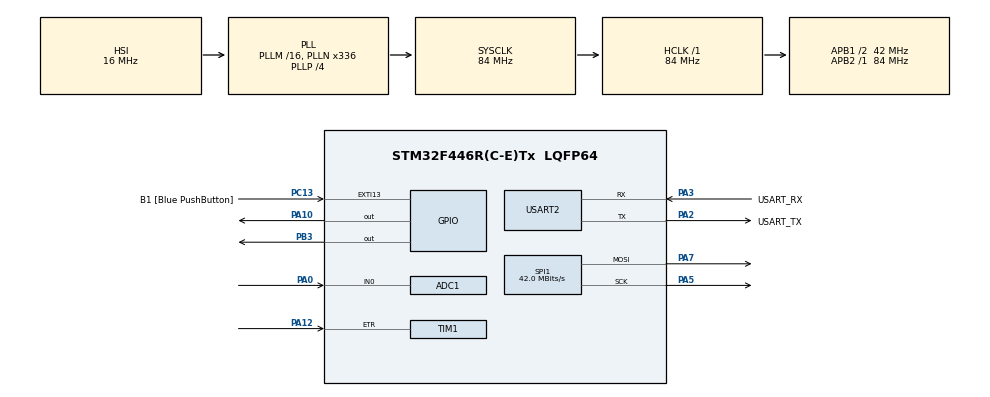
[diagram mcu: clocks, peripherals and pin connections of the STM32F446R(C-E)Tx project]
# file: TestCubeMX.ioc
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ADC1.Channel-6\#ChannelRegularConversion=ADC_CHANNEL_0
ADC1.NbrOfConversionFlag=1
ADC1.Rank-6\#ChannelRegularConversion=1
ADC1.SamplingTime-6\#ChannelRegularConversion=ADC_SAMPLETIME_3CYCLES
ADC1.master=1
Dma.Request0=SPI1_TX
Dma.SPI1_TX.0.Direction=DMA_MEMORY_TO_PERIPH
Dma.SPI1_TX.0.FIFOMode=DMA_FIFOMODE_DISABLE
Dma.SPI1_TX.0.Instance=DMA2_Stream3
Dma.SPI1_TX.0.MemDataAlignment=DMA_MDATAALIGN_BYTE
Dma.SPI1_TX.0.MemInc=DMA_MINC_ENABLE
Dma.SPI1_TX.0.Mode=DMA_NORMAL
Dma.SPI1_TX.0.PeriphDataAlignment=DMA_PDATAALIGN_BYTE
Dma.SPI1_TX.0.PeriphInc=DMA_PINC_DISABLE
Dma.SPI1_TX.0.Priority=DMA_PRIORITY_HIGH
Mcu.Family=STM32F4
Mcu.Name=STM32F446R(C-E)Tx
Mcu.Package=LQFP64
NVIC.DMA2_Stream3_IRQn=true\:0\:0\:false\:false\:true\:false\:true
NVIC.PriorityGroup=NVIC_PRIORITYGROUP_0
PA0-WKUP.Signal=ADCx_IN0
PA10.Signal=GPIO_Output
PA12.Signal=S_TIM1_ETR
PA13.GPIO_Label=TMS
PA13.Mode=Serial_Wire
PA13.Signal=SYS_JTMS-SWDIO
PA14.GPIO_Label=TCK
PA14.Mode=Serial_Wire
PA14.Signal=SYS_JTCK-SWCLK
PA2.GPIO_Label=USART_TX
PA2.Mode=Asynchronous
PA2.Signal=USART2_TX
PA3.GPIO_Label=USART_RX
PA3.Mode=Asynchronous
PA3.Signal=USART2_RX
PA5.Mode=TX_Only_Simplex_Unidirect_Master
PA5.Signal=SPI1_SCK
PA7.Mode=TX_Only_Simplex_Unidirect_Master
PA7.Signal=SPI1_MOSI
PB3.Signal=GPIO_Output
PC13.GPIO_Label=B1 [Blue PushButton]
PC13.GPIO_ModeDefaultEXTI=GPIO_MODE_IT_FALLING
PC13.Signal=GPXTI13
PC14-OSC32_IN.Mode=LSE-External-Oscillator
PC14-OSC32_IN.Signal=RCC_OSC32_IN
PC15-OSC32_OUT.Mode=LSE-External-Oscillator
PC15-OSC32_OUT.Signal=RCC_OSC32_OUT
PH0-OSC_IN.Mode=HSE-External-Oscillator
PH0-OSC_IN.Signal=RCC_OSC_IN
PH1-OSC_OUT.Mode=HSE-External-Oscillator
PH1-OSC_OUT.Signal=RCC_OSC_OUT
ProjectManager.HeapSize=0x200
ProjectManager.StackSize=0x400
ProjectManager.TargetToolchain=STM32CubeIDE
RCC.48MHZClocksFreq_Value=84000000
RCC.AHBFreq_Value=84000000
RCC.APB1CLKDivider=RCC_HCLK_DIV2
RCC.APB1Freq_Value=42000000
RCC.APB1TimFreq_Value=84000000
RCC.APB2Freq_Value=84000000
RCC.APB2TimFreq_Value=84000000
RCC.CortexFreq_Value=84000000
RCC.FLatency-AdvancedSettings=FLASH_LATENCY_2
RCC.HCLKFreq_Value=84000000
RCC.HSE_VALUE=8000000
RCC.HSI_VALUE=16000000
RCC.PLLN=336
RCC.PLLP=RCC_PLLP_DIV4
RCC.SYSCLKFreq_VALUE=84000000
RCC.SYSCLKSource=RCC_SYSCLKSOURCE_PLLCLK
RCC.USBFreq_Value=168000000
RCC.VCOOutputFreq_Value=336000000
SH.ADCx_IN0.0=ADC1_IN0,IN0
SH.S_TIM1_ETR.0=TIM1_ETR,TriggerSource_ETR
SPI1.CalculateBaudRate=42.0 MBits/s
SPI1.DataSize=SPI_DATASIZE_8BIT
SPI1.Direction=SPI_DIRECTION_2LINES
SPI1.Mode=SPI_MODE_MASTER
SPI1.VirtualType=VM_MASTER
TIM1.Channel-Output\ Compare1\ No\ Output=TIM_CHANNEL_1
USART2.VirtualMode=VM_ASYNC
VP_TIM1_VS_ControllerModeClock.Mode=Clock Mode
VP_TIM1_VS_no_output1.Mode=Output Compare1 No Output
board=NUCLEO-F446RE

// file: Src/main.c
/* USER CODE BEGIN Header */
/**
  ******************************************************************************
  * @file           : main.c
  * @brief          : Main program body
  ******************************************************************************
  * @attention
  *
  * <h2><center>&copy; Copyright (c) 2020 STMicroelectronics.
  * All rights reserved.</center></h2>
  *
  * This software component is licensed by ST under BSD 3-Clause license,
  * the "License"; You may not use this file except in compliance with the
  * License. You may obtain a copy of the License at:
  *                        opensource.org/licenses/BSD-3-Clause
  *
  ******************************************************************************
  */
/* USER CODE END Header */

#include "main.h"

ADC_HandleTypeDef hadc1;

SPI_HandleTypeDef hspi1;
DMA_HandleTypeDef hdma_spi1_tx;

TIM_HandleTypeDef htim1;

UART_HandleTypeDef huart2;

void SystemClock_Config(void);
static void MX_GPIO_Init(void);
static void MX_DMA_Init(void);
static void MX_USART2_UART_Init(void);
static void MX_SPI1_Init(void);
static void MX_TIM1_Init(void);
static void MX_ADC1_Init(void);

int main(void)
{

  /* MCU Configuration--------------------------------------------------------*/

  /* Reset of all peripherals, Initializes the Flash interface and the Systick. */
  HAL_Init();

  /* Configure the system clock */
  SystemClock_Config();

  /* Initialize all configured peripherals */
  MX_GPIO_Init();
  MX_DMA_Init();
  MX_USART2_UART_Init();
  MX_SPI1_Init();
  MX_TIM1_Init();
  MX_ADC1_Init();

  /* Infinite loop */
  /* USER CODE BEGIN WHILE */
  // muxout -> pa12
  // CLK -> D13 -> PA5 -> SPI1 C
  // DATA -> D11 -> PA7 -> SPI1_MOSI
  // LE -> D2 -> PA10
  // CE -> D3 -> PB3
  // RFOUT -> D4 ->PB5
  HAL_GPIO_WritePin(GPIOB, GPIO_PIN_3, GPIO_PIN_SET);
  HAL_GPIO_WritePin(GPIOA, GPIO_PIN_10, GPIO_PIN_RESET);
  HAL_StatusTypeDef result = HAL_OK;
  while (1)
  {
    uint8_t buf[4];
    result = HAL_UART_Receive(&huart2, buf, sizeof(buf), 1000);
    if(result == HAL_OK) {
      uint32_t reg = ((buf)[0] << 24) | ((buf)[1] << 16) | ((buf)[2] << 8) | (buf)[3];
      HAL_GPIO_WritePin(GPIOA, GPIO_PIN_10, GPIO_PIN_SET);
      result = HAL_SPI_Transmit(&hspi1, buf, sizeof(buf), 1000);
      if(result == HAL_OK) {
        HAL_UART_Transmit(&huart2, buf, sizeof(buf), 1000);
      }
    }
    /* USER CODE END WHILE */

  }
}

void SystemClock_Config(void)
{
  RCC_OscInitTypeDef RCC_OscInitStruct = {0};
  RCC_ClkInitTypeDef RCC_ClkInitStruct = {0};

  /** Configure the main internal regulator output voltage
  */
  __HAL_RCC_PWR_CLK_ENABLE();
  __HAL_PWR_VOLTAGESCALING_CONFIG(PWR_REGULATOR_VOLTAGE_SCALE3);
  /** Initializes the CPU, AHB and APB busses clocks
  */
  RCC_OscInitStruct.OscillatorType = RCC_OSCILLATORTYPE_HSI;
  RCC_OscInitStruct.HSIState = RCC_HSI_ON;
  RCC_OscInitStruct.HSICalibrationValue = RCC_HSICALIBRATION_DEFAULT;
  RCC_OscInitStruct.PLL.PLLState = RCC_PLL_ON;
  RCC_OscInitStruct.PLL.PLLSource = RCC_PLLSOURCE_HSI;
  RCC_OscInitStruct.PLL.PLLM = 16;
  RCC_OscInitStruct.PLL.PLLN = 336;
  RCC_OscInitStruct.PLL.PLLP = RCC_PLLP_DIV4;
  RCC_OscInitStruct.PLL.PLLQ = 2;
  RCC_OscInitStruct.PLL.PLLR = 2;
  if (HAL_RCC_OscConfig(&RCC_OscInitStruct) != HAL_OK)
  {
    Error_Handler();
  }
  /** Initializes the CPU, AHB and APB busses clocks
  */
  RCC_ClkInitStruct.ClockType = RCC_CLOCKTYPE_HCLK|RCC_CLOCKTYPE_SYSCLK
                              |RCC_CLOCKTYPE_PCLK1|RCC_CLOCKTYPE_PCLK2;
  RCC_ClkInitStruct.SYSCLKSource = RCC_SYSCLKSOURCE_PLLCLK;
  RCC_ClkInitStruct.AHBCLKDivider = RCC_SYSCLK_DIV1;
  RCC_ClkInitStruct.APB1CLKDivider = RCC_HCLK_DIV2;
  RCC_ClkInitStruct.APB2CLKDivider = RCC_HCLK_DIV1;

  if (HAL_RCC_ClockConfig(&RCC_ClkInitStruct, FLASH_LATENCY_2) != HAL_OK)
  {
    Error_Handler();
  }
}

static void MX_ADC1_Init(void)
{

  ADC_ChannelConfTypeDef sConfig = {0};

  /** Configure the global features of the ADC (Clock, Resolution, Data Alignment and number of conversion)
  */
  hadc1.Instance = ADC1;
  hadc1.Init.ClockPrescaler = ADC_CLOCK_SYNC_PCLK_DIV4;
  hadc1.Init.Resolution = ADC_RESOLUTION_12B;
  hadc1.Init.ScanConvMode = DISABLE;
  hadc1.Init.ContinuousConvMode = DISABLE;
  hadc1.Init.DiscontinuousConvMode = DISABLE;
  hadc1.Init.ExternalTrigConvEdge = ADC_EXTERNALTRIGCONVEDGE_NONE;
  hadc1.Init.ExternalTrigConv = ADC_SOFTWARE_START;
  hadc1.Init.DataAlign = ADC_DATAALIGN_RIGHT;
  hadc1.Init.NbrOfConversion = 1;
  hadc1.Init.DMAContinuousRequests = DISABLE;
  hadc1.Init.EOCSelection = ADC_EOC_SINGLE_CONV;
  if (HAL_ADC_Init(&hadc1) != HAL_OK)
  {
    Error_Handler();
  }
  /** Configure for the selected ADC regular channel its corresponding rank in the sequencer and its sample time.
  */
  sConfig.Channel = ADC_CHANNEL_0;
  sConfig.Rank = 1;
  sConfig.SamplingTime = ADC_SAMPLETIME_3CYCLES;
  if (HAL_ADC_ConfigChannel(&hadc1, &sConfig) != HAL_OK)
  {
    Error_Handler();
  }

}

static void MX_SPI1_Init(void)
{

  /* SPI1 parameter configuration*/
  hspi1.Instance = SPI1;
  hspi1.Init.Mode = SPI_MODE_MASTER;
  hspi1.Init.Direction = SPI_DIRECTION_2LINES;
  hspi1.Init.DataSize = SPI_DATASIZE_8BIT;
  hspi1.Init.CLKPolarity = SPI_POLARITY_LOW;
  hspi1.Init.CLKPhase = SPI_PHASE_1EDGE;
  hspi1.Init.NSS = SPI_NSS_SOFT;
  hspi1.Init.BaudRatePrescaler = SPI_BAUDRATEPRESCALER_2;
  hspi1.Init.FirstBit = SPI_FIRSTBIT_MSB;
  hspi1.Init.TIMode = SPI_TIMODE_DISABLE;
  hspi1.Init.CRCCalculation = SPI_CRCCALCULATION_DISABLE;
  hspi1.Init.CRCPolynomial = 10;
  if (HAL_SPI_Init(&hspi1) != HAL_OK)
  {
    Error_Handler();
  }

}

static void MX_TIM1_Init(void)
{

  TIM_SlaveConfigTypeDef sSlaveConfig = {0};
  TIM_MasterConfigTypeDef sMasterConfig = {0};
  TIM_OC_InitTypeDef sConfigOC = {0};
  TIM_BreakDeadTimeConfigTypeDef sBreakDeadTimeConfig = {0};

  htim1.Instance = TIM1;
  htim1.Init.Prescaler = 0;
  htim1.Init.CounterMode = TIM_COUNTERMODE_UP;
  htim1.Init.Period = 0;
  htim1.Init.ClockDivision = TIM_CLOCKDIVISION_DIV1;
  htim1.Init.RepetitionCounter = 0;
  htim1.Init.AutoReloadPreload = TIM_AUTORELOAD_PRELOAD_DISABLE;
  if (HAL_TIM_Base_Init(&htim1) != HAL_OK)
  {
    Error_Handler();
  }
  if (HAL_TIM_OC_Init(&htim1) != HAL_OK)
  {
    Error_Handler();
  }
  sSlaveConfig.SlaveMode = TIM_SLAVEMODE_EXTERNAL1;
  sSlaveConfig.InputTrigger = TIM_TS_ETRF;
  sSlaveConfig.TriggerPolarity = TIM_TRIGGERPOLARITY_NONINVERTED;
  sSlaveConfig.TriggerPrescaler = TIM_TRIGGERPRESCALER_DIV1;
  sSlaveConfig.TriggerFilter = 0;
  if (HAL_TIM_SlaveConfigSynchro(&htim1, &sSlaveConfig) != HAL_OK)
  {
    Error_Handler();
  }
  sMasterConfig.MasterOutputTrigger = TIM_TRGO_RESET;
  sMasterConfig.MasterSlaveMode = TIM_MASTERSLAVEMODE_DISABLE;
  if (HAL_TIMEx_MasterConfigSynchronization(&htim1, &sMasterConfig) != HAL_OK)
  {
    Error_Handler();
  }
  sConfigOC.OCMode = TIM_OCMODE_TIMING;
  sConfigOC.Pulse = 0;
  sConfigOC.OCPolarity = TIM_OCPOLARITY_HIGH;
  sConfigOC.OCNPolarity = TIM_OCNPOLARITY_HIGH;
  sConfigOC.OCFastMode = TIM_OCFAST_DISABLE;
  sConfigOC.OCIdleState = TIM_OCIDLESTATE_RESET;
  sConfigOC.OCNIdleState = TIM_OCNIDLESTATE_RESET;
  if (HAL_TIM_OC_ConfigChannel(&htim1, &sConfigOC, TIM_CHANNEL_1) != HAL_OK)
  {
    Error_Handler();
  }
  sBreakDeadTimeConfig.OffStateRunMode = TIM_OSSR_DISABLE;
  sBreakDeadTimeConfig.OffStateIDLEMode = TIM_OSSI_DISABLE;
  sBreakDeadTimeConfig.LockLevel = TIM_LOCKLEVEL_OFF;
  sBreakDeadTimeConfig.DeadTime = 0;
  sBreakDeadTimeConfig.BreakState = TIM_BREAK_DISABLE;
  sBreakDeadTimeConfig.BreakPolarity = TIM_BREAKPOLARITY_HIGH;
  sBreakDeadTimeConfig.AutomaticOutput = TIM_AUTOMATICOUTPUT_DISABLE;
  if (HAL_TIMEx_ConfigBreakDeadTime(&htim1, &sBreakDeadTimeConfig) != HAL_OK)
  {
    Error_Handler();
  }

}

static void MX_USART2_UART_Init(void)
{

  huart2.Instance = USART2;
  huart2.Init.BaudRate = 115200;
  huart2.Init.WordLength = UART_WORDLENGTH_8B;
  huart2.Init.StopBits = UART_STOPBITS_1;
  huart2.Init.Parity = UART_PARITY_NONE;
  huart2.Init.Mode = UART_MODE_TX_RX;
  huart2.Init.HwFlowCtl = UART_HWCONTROL_NONE;
  huart2.Init.OverSampling = UART_OVERSAMPLING_16;
  if (HAL_UART_Init(&huart2) != HAL_OK)
  {
    Error_Handler();
  }

}

static void MX_DMA_Init(void)
{

  /* DMA controller clock enable */
  __HAL_RCC_DMA2_CLK_ENABLE();

  /* DMA interrupt init */
  /* DMA2_Stream3_IRQn interrupt configuration */
  HAL_NVIC_SetPriority(DMA2_Stream3_IRQn, 0, 0);
  HAL_NVIC_EnableIRQ(DMA2_Stream3_IRQn);

}

static void MX_GPIO_Init(void)
{
  GPIO_InitTypeDef GPIO_InitStruct = {0};

  /* GPIO Ports Clock Enable */
  __HAL_RCC_GPIOC_CLK_ENABLE();
  __HAL_RCC_GPIOH_CLK_ENABLE();
  __HAL_RCC_GPIOA_CLK_ENABLE();
  __HAL_RCC_GPIOB_CLK_ENABLE();

  /*Configure GPIO pin Output Level */
  HAL_GPIO_WritePin(GPIOA, GPIO_PIN_10, GPIO_PIN_RESET);

  /*Configure GPIO pin Output Level */
  HAL_GPIO_WritePin(GPIOB, GPIO_PIN_3, GPIO_PIN_RESET);

  /*Configure GPIO pin : B1_Pin */
  GPIO_InitStruct.Pin = B1_Pin;
  GPIO_InitStruct.Mode = GPIO_MODE_IT_FALLING;
  GPIO_InitStruct.Pull = GPIO_NOPULL;
  HAL_GPIO_Init(B1_GPIO_Port, &GPIO_InitStruct);

  /*Configure GPIO pin : PA10 */
  GPIO_InitStruct.Pin = GPIO_PIN_10;
  GPIO_InitStruct.Mode = GPIO_MODE_OUTPUT_PP;
  GPIO_InitStruct.Pull = GPIO_NOPULL;
  GPIO_InitStruct.Speed = GPIO_SPEED_FREQ_LOW;
  HAL_GPIO_Init(GPIOA, &GPIO_InitStruct);

  /*Configure GPIO pin : PB3 */
  GPIO_InitStruct.Pin = GPIO_PIN_3;
  GPIO_InitStruct.Mode = GPIO_MODE_OUTPUT_PP;
  GPIO_InitStruct.Pull = GPIO_NOPULL;
  GPIO_InitStruct.Speed = GPIO_SPEED_FREQ_LOW;
  HAL_GPIO_Init(GPIOB, &GPIO_InitStruct);

}

void Error_Handler(void)
{
}

/************************ (C) COPYRIGHT STMicroelectronics *****END OF FILE****/
